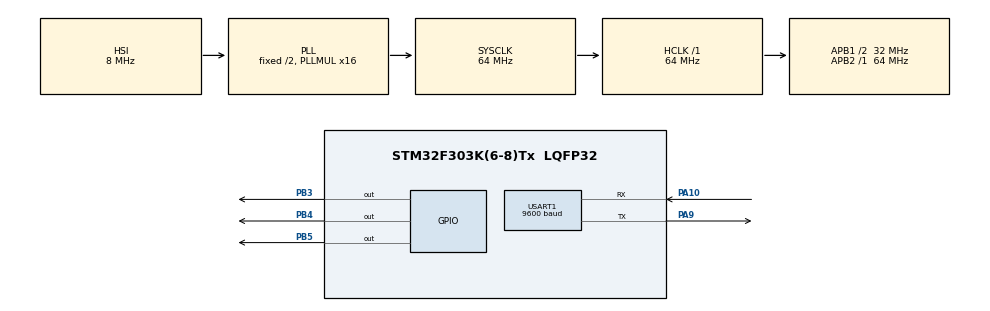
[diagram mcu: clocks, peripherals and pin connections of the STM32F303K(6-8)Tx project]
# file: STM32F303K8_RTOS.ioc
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FREERTOS.INCLUDE_eTaskGetState=1
FREERTOS.INCLUDE_vTaskDelayUntil=1
FREERTOS.Tasks01=defaultTask,3,128,StartDefaultTask,Default,NULL,Dynamic,NULL,NULL;myTask02,2,128,StartTask02,Default,NULL,Dynamic,NULL,NULL;myTask03,1,128,StartTask03,Default,NULL,Dynamic,NULL,NULL
FREERTOS.configCHECK_FOR_STACK_OVERFLOW=1
FREERTOS.configUSE_ALTERNATIVE_API=0
FREERTOS.configUSE_IDLE_HOOK=1
FREERTOS.configUSE_TIMERS=0
Mcu.Family=STM32F3
Mcu.Name=STM32F303K(6-8)Tx
Mcu.Package=LQFP32
NVIC.PriorityGroup=NVIC_PRIORITYGROUP_4
NVIC.TIM1_UP_TIM16_IRQn=true\:0\:0\:false\:false\:true\:false
NVIC.TimeBase=TIM1_UP_TIM16_IRQn
NVIC.TimeBaseIP=TIM1
PA10.Mode=Asynchronous
PA10.Signal=USART1_RX
PA13.GPIO_Label=SWDIO
PA13.Mode=Serial_Wire
PA13.Signal=SYS_JTMS-SWDIO
PA14.GPIO_Label=SWCLK
PA14.Mode=Serial_Wire
PA14.Signal=SYS_JTCK-SWCLK
PA15.GPIO_Label=VCP_RX
PA15.Signal=USART2_RX
PA2.GPIO_Label=VCP_TX
PA2.Signal=USART2_TX
PA9.Mode=Asynchronous
PA9.Signal=USART1_TX
PB3.GPIO_Speed=GPIO_SPEED_FREQ_HIGH
PB3.Signal=GPIO_Output
PB4.GPIO_Speed=GPIO_SPEED_FREQ_HIGH
PB4.Signal=GPIO_Output
PB5.Signal=GPIO_Output
PF0\ /\ OSC_IN.GPIO_Label=MCO
PF0\ /\ OSC_IN.Signal=RCC_OSC_IN
ProjectManager.HeapSize=0x200
ProjectManager.StackSize=0x400
ProjectManager.TargetToolchain=SW4STM32
RCC.ADC1Enable=false
RCC.ADC2Enable=false
RCC.ADC3Enable=false
RCC.ADC4Enable=false
RCC.AHBFreq_Value=64000000
RCC.APB1CLKDivider=RCC_HCLK_DIV2
RCC.APB1Freq_Value=32000000
RCC.APB1TimFreq_Value=64000000
RCC.APB2Freq_Value=64000000
RCC.APB2TimFreq_Value=64000000
RCC.ClockTypeHCLK=RCC_CLOCKTYPE_HCLK
RCC.ClockTypePCLK1=RCC_CLOCKTYPE_PCLK1
RCC.ClockTypePCLK2=RCC_CLOCKTYPE_PCLK2
RCC.CortexFreq_Value=64000000
RCC.EnableHSE=false
RCC.EnableHSERTCDevisor=false
RCC.EnableHSIRTCDevisor=false
RCC.EnableLSE=false
RCC.EnableLSERTC=false
RCC.EnableMCOMultDivisor=false
RCC.FLITFCLKFEnable=false
RCC.HCLKFreq_Value=64000000
RCC.HRTIMEnable=false
RCC.HSEState=RCC_HSE_OFF
RCC.HSE_VALUE=8000000
RCC.HSIState=RCC_HSI_ON
RCC.HSI_VALUE=8000000
RCC.I2C1Enable=false
RCC.I2C2Enable=false
RCC.I2C3Enable=false
RCC.I2SEnable=false
RCC.IWDGEnable=false
RCC.LSIState=RCC_LSI_OFF
RCC.MCOEnable=false
RCC.OscillatorTypeHSI=RCC_OSCILLATORTYPE_HSI
RCC.PLLMUL=RCC_PLL_MUL16
RCC.PLLSource=RCC_PLLSOURCE_HSI
RCC.PLLSourceVirtual=RCC_PLLSOURCE_HSI
RCC.PLLState=RCC_PLL_ON
RCC.RCC_PERIPHCLK_TIM1Var=RCC_PERIPHCLK_TIM1
RCC.RCC_PERIPHCLK_USART1Var=RCC_PERIPHCLK_USART1
RCC.RTCEnable=false
RCC.SYSCLKFreq_VALUE=64000000
RCC.SYSCLKSource=RCC_SYSCLKSOURCE_PLLCLK
RCC.SYSCLKSourceVirtual=RCC_SYSCLKSOURCE_PLLCLK
RCC.Tim15Enable=false
RCC.Tim16Enable=false
RCC.Tim17Enable=false
RCC.Tim1Enable=false
RCC.Tim8Enable=true
RCC.UART4Enable=false
RCC.UART5Enable=false
RCC.USART1Enable=true
RCC.USART2Enable=false
RCC.USART3Enable=false
RCC.USBEnable=false
SYS.instance=TIM1
USART1.BaudRate=9600
USART1.HwFlowCtl-Asynchronous=UART_HWCONTROL_NONE
USART1.VirtualMode-Asynchronous=VM_ASYNC
USART1.WordLength=WORDLENGTH_8B
VP_FREERTOS_VS_ENABLE.Mode=Enabled
VP_SYS_VS_tim1.Mode=TIM1
board=NUCLEO-F303K8

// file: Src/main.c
/**
  ******************************************************************************
  * File Name          : main.c
  * Description        : Main program body
  ******************************************************************************
  *
  * Copyright (c) 2017 STMicroelectronics International N.V.
  * All rights reserved.
  *
  * Redistribution and use in source and binary forms, with or without
  * modification, are permitted, provided that the following conditions are met:
  *
  * 1. Redistribution of source code must retain the above copyright notice,
  *    this list of conditions and the following disclaimer.
  * 2. Redistributions in binary form must reproduce the above copyright notice,
  *    this list of conditions and the following disclaimer in the documentation
  *    and/or other materials provided with the distribution.
  * 3. Neither the name of STMicroelectronics nor the names of other
  *    contributors to this software may be used to endorse or promote products
  *    derived from this software without specific written permission.
  * 4. This software, including modifications and/or derivative works of this
  *    software, must execute solely and exclusively on microcontroller or
  *    microprocessor devices manufactured by or for STMicroelectronics.
  * 5. Redistribution and use of this software other than as permitted under
  *    this license is void and will automatically terminate your rights under
  *    this license.
  *
  * THIS SOFTWARE IS PROVIDED BY STMICROELECTRONICS AND CONTRIBUTORS "AS IS"
  * AND ANY EXPRESS, IMPLIED OR STATUTORY WARRANTIES, INCLUDING, BUT NOT
  * LIMITED TO, THE IMPLIED WARRANTIES OF MERCHANTABILITY, FITNESS FOR A
  * PARTICULAR PURPOSE AND NON-INFRINGEMENT OF THIRD PARTY INTELLECTUAL PROPERTY
  * RIGHTS ARE DISCLAIMED TO THE FULLEST EXTENT PERMITTED BY LAW. IN NO EVENT
  * SHALL STMICROELECTRONICS OR CONTRIBUTORS BE LIABLE FOR ANY DIRECT, INDIRECT,
  * INCIDENTAL, SPECIAL, EXEMPLARY, OR CONSEQUENTIAL DAMAGES (INCLUDING, BUT NOT
  * LIMITED TO, PROCUREMENT OF SUBSTITUTE GOODS OR SERVICES; LOSS OF USE, DATA,
  * OR PROFITS; OR BUSINESS INTERRUPTION) HOWEVER CAUSED AND ON ANY THEORY OF
  * LIABILITY, WHETHER IN CONTRACT, STRICT LIABILITY, OR TORT (INCLUDING
  * NEGLIGENCE OR OTHERWISE) ARISING IN ANY WAY OUT OF THE USE OF THIS SOFTWARE,
  * EVEN IF ADVISED OF THE POSSIBILITY OF SUCH DAMAGE.
  *
  ******************************************************************************
  */
#include "main.h"
#include "stm32f3xx_hal.h"
#include "cmsis_os.h"

UART_HandleTypeDef huart1;

osThreadId defaultTaskHandle;
osThreadId myTask02Handle;
osThreadId myTask03Handle;

/* USER CODE BEGIN PV */
/* Private variables ---------------------------------------------------------*/

/* USER CODE END PV */

void SystemClock_Config(void);
void Error_Handler(void);
static void MX_GPIO_Init(void);
static void MX_USART1_UART_Init(void);
void StartDefaultTask(void const * argument);
void StartTask02(void const * argument);
void StartTask03(void const * argument);

/* USER CODE BEGIN PFP */
/* Private function prototypes -----------------------------------------------*/

/* USER CODE END PFP */

int main(void)
{

  /* MCU Configuration----------------------------------------------------------*/

  /* Reset of all peripherals, Initializes the Flash interface and the Systick. */
  HAL_Init();

  /* Configure the system clock */
  SystemClock_Config();

  /* Initialize all configured peripherals */
  MX_GPIO_Init();
  MX_USART1_UART_Init();

  /* Create the thread(s) */
  /* definition and creation of defaultTask */
  osThreadDef(defaultTask, StartDefaultTask, osPriorityRealtime, 0, 128);
  defaultTaskHandle = osThreadCreate(osThread(defaultTask), NULL);

  /* definition and creation of myTask02 */
  osThreadDef(myTask02, StartTask02, osPriorityHigh, 0, 128);
  myTask02Handle = osThreadCreate(osThread(myTask02), NULL);
//
//  /* definition and creation of myTask03 */
  osThreadDef(myTask03, StartTask03, osPriorityAboveNormal, 0, 128);
  myTask03Handle = osThreadCreate(osThread(myTask03), NULL);

  /* Start scheduler */
  osKernelStart();

  /* We should never get here as control is now taken by the scheduler */

  /* Infinite loop */
  while (1)
  {

  }

}

/** System Clock Configuration
*/
void SystemClock_Config(void)
{

  RCC_OscInitTypeDef RCC_OscInitStruct;
  RCC_ClkInitTypeDef RCC_ClkInitStruct;
  RCC_PeriphCLKInitTypeDef PeriphClkInit;

    /**Initializes the CPU, AHB and APB busses clocks
    */
  RCC_OscInitStruct.OscillatorType = RCC_OSCILLATORTYPE_HSI;
  RCC_OscInitStruct.HSIState = RCC_HSI_ON;
  RCC_OscInitStruct.HSICalibrationValue = 16;
  RCC_OscInitStruct.PLL.PLLState = RCC_PLL_ON;
  RCC_OscInitStruct.PLL.PLLSource = RCC_PLLSOURCE_HSI;
  RCC_OscInitStruct.PLL.PLLMUL = RCC_PLL_MUL16;
  if (HAL_RCC_OscConfig(&RCC_OscInitStruct) != HAL_OK)
  {
    Error_Handler();
  }

    /**Initializes the CPU, AHB and APB busses clocks
    */
  RCC_ClkInitStruct.ClockType = RCC_CLOCKTYPE_HCLK|RCC_CLOCKTYPE_SYSCLK
                              |RCC_CLOCKTYPE_PCLK1|RCC_CLOCKTYPE_PCLK2;
  RCC_ClkInitStruct.SYSCLKSource = RCC_SYSCLKSOURCE_PLLCLK;
  RCC_ClkInitStruct.AHBCLKDivider = RCC_SYSCLK_DIV1;
  RCC_ClkInitStruct.APB1CLKDivider = RCC_HCLK_DIV2;
  RCC_ClkInitStruct.APB2CLKDivider = RCC_HCLK_DIV1;

  if (HAL_RCC_ClockConfig(&RCC_ClkInitStruct, FLASH_LATENCY_2) != HAL_OK)
  {
    Error_Handler();
  }

  PeriphClkInit.PeriphClockSelection = RCC_PERIPHCLK_USART1|RCC_PERIPHCLK_TIM1;
  PeriphClkInit.Usart1ClockSelection = RCC_USART1CLKSOURCE_PCLK1;
  if (HAL_RCCEx_PeriphCLKConfig(&PeriphClkInit) != HAL_OK)
  {
    Error_Handler();
  }

    /**Configure the Systick interrupt time
    */
  HAL_SYSTICK_Config(HAL_RCC_GetHCLKFreq()/1000);

    /**Configure the Systick
    */
  HAL_SYSTICK_CLKSourceConfig(SYSTICK_CLKSOURCE_HCLK);

  /* SysTick_IRQn interrupt configuration */
  HAL_NVIC_SetPriority(SysTick_IRQn, 15, 0);
}

/* USART1 init function */
static void MX_USART1_UART_Init(void)
{

  huart1.Instance = USART1;
  huart1.Init.BaudRate = 9600;
  huart1.Init.WordLength = UART_WORDLENGTH_8B;
  huart1.Init.StopBits = UART_STOPBITS_1;
  huart1.Init.Parity = UART_PARITY_NONE;
  huart1.Init.Mode = UART_MODE_TX_RX;
  huart1.Init.HwFlowCtl = UART_HWCONTROL_NONE;
  huart1.Init.OverSampling = UART_OVERSAMPLING_16;
  huart1.Init.OneBitSampling = UART_ONE_BIT_SAMPLE_DISABLE;
  huart1.AdvancedInit.AdvFeatureInit = UART_ADVFEATURE_NO_INIT;
  if (HAL_UART_Init(&huart1) != HAL_OK)
  {
    Error_Handler();
  }

}

/** Configure pins as
        * Analog
        * Input
        * Output
        * EVENT_OUT
        * EXTI
     PA2   ------> USART2_TX
     PA15   ------> USART2_RX
*/
static void MX_GPIO_Init(void)
{

  GPIO_InitTypeDef GPIO_InitStruct;

  /* GPIO Ports Clock Enable */
  __HAL_RCC_GPIOF_CLK_ENABLE();
  __HAL_RCC_GPIOA_CLK_ENABLE();
  __HAL_RCC_GPIOB_CLK_ENABLE();

  /*Configure GPIO pin Output Level */
  HAL_GPIO_WritePin(GPIOB, GPIO_PIN_3|GPIO_PIN_4|GPIO_PIN_5, GPIO_PIN_RESET);

  /*Configure GPIO pins : VCP_TX_Pin VCP_RX_Pin */
  GPIO_InitStruct.Pin = VCP_TX_Pin|VCP_RX_Pin;
  GPIO_InitStruct.Mode = GPIO_MODE_AF_PP;
  GPIO_InitStruct.Pull = GPIO_NOPULL;
  GPIO_InitStruct.Speed = GPIO_SPEED_FREQ_HIGH;
  GPIO_InitStruct.Alternate = GPIO_AF7_USART2;
  HAL_GPIO_Init(GPIOA, &GPIO_InitStruct);

  /*Configure GPIO pins : PB3 PB4 */
  GPIO_InitStruct.Pin = GPIO_PIN_3|GPIO_PIN_4;
  GPIO_InitStruct.Mode = GPIO_MODE_OUTPUT_PP;
  GPIO_InitStruct.Pull = GPIO_NOPULL;
  GPIO_InitStruct.Speed = GPIO_SPEED_FREQ_HIGH;
  HAL_GPIO_Init(GPIOB, &GPIO_InitStruct);

  /*Configure GPIO pin : PB5 */
  GPIO_InitStruct.Pin = GPIO_PIN_5;
  GPIO_InitStruct.Mode = GPIO_MODE_OUTPUT_PP;
  GPIO_InitStruct.Pull = GPIO_NOPULL;
  GPIO_InitStruct.Speed = GPIO_SPEED_FREQ_LOW;
  HAL_GPIO_Init(GPIOB, &GPIO_InitStruct);

}

/* StartDefaultTask function */
void StartDefaultTask(void const * argument)
{

  /* USER CODE BEGIN 5 */
  /* Infinite loop */
  uint32_t PreviousWakeTime = osKernelSysTick();
  for(;;)
  {
	  HAL_GPIO_TogglePin(GPIOB, GPIO_PIN_3);
	  //osDelay(1);
	  osDelayUntil (&PreviousWakeTime, 1);
  }
  /* USER CODE END 5 */
}

/* StartTask02 function */
void StartTask02(void const * argument)
{
  /* USER CODE BEGIN StartTask02 */
  /* Infinite loop */
  uint32_t PreviousWakeTime = osKernelSysTick();
  for(;;)
  {
	HAL_GPIO_TogglePin(GPIOB, GPIO_PIN_4);
    //osDelay(1);
    osDelayUntil (&PreviousWakeTime, 1);
  }
  /* USER CODE END StartTask02 */
}

/* StartTask03 function */
void StartTask03(void const * argument)
{
  /* USER CODE BEGIN StartTask03 */
  /* Infinite loop */
  uint32_t PreviousWakeTime = osKernelSysTick();
  for(;;)
  {
	  HAL_GPIO_TogglePin(GPIOB, GPIO_PIN_5);
    //osDelay(1);
	  osDelayUntil (&PreviousWakeTime, 1);
  }
  /* USER CODE END StartTask03 */
}

void HAL_TIM_PeriodElapsedCallback(TIM_HandleTypeDef *htim)
{
  if (htim->Instance == TIM1) {
    HAL_IncTick();
  }
}

void Error_Handler(void)
{
  while(1)
  {
  }
}

/************************ (C) COPYRIGHT STMicroelectronics *****END OF FILE****/

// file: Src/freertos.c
/**
  ******************************************************************************
  * File Name          : freertos.c
  * Description        : Code for freertos applications
  ******************************************************************************
  *
  * Copyright (c) 2017 STMicroelectronics International N.V.
  * All rights reserved.
  *
  * Redistribution and use in source and binary forms, with or without
  * modification, are permitted, provided that the following conditions are met:
  *
  * 1. Redistribution of source code must retain the above copyright notice,
  *    this list of conditions and the following disclaimer.
  * 2. Redistributions in binary form must reproduce the above copyright notice,
  *    this list of conditions and the following disclaimer in the documentation
  *    and/or other materials provided with the distribution.
  * 3. Neither the name of STMicroelectronics nor the names of other
  *    contributors to this software may be used to endorse or promote products
  *    derived from this software without specific written permission.
  * 4. This software, including modifications and/or derivative works of this
  *    software, must execute solely and exclusively on microcontroller or
  *    microprocessor devices manufactured by or for STMicroelectronics.
  * 5. Redistribution and use of this software other than as permitted under
  *    this license is void and will automatically terminate your rights under
  *    this license.
  *
  * THIS SOFTWARE IS PROVIDED BY STMICROELECTRONICS AND CONTRIBUTORS "AS IS"
  * AND ANY EXPRESS, IMPLIED OR STATUTORY WARRANTIES, INCLUDING, BUT NOT
  * LIMITED TO, THE IMPLIED WARRANTIES OF MERCHANTABILITY, FITNESS FOR A
  * PARTICULAR PURPOSE AND NON-INFRINGEMENT OF THIRD PARTY INTELLECTUAL PROPERTY
  * RIGHTS ARE DISCLAIMED TO THE FULLEST EXTENT PERMITTED BY LAW. IN NO EVENT
  * SHALL STMICROELECTRONICS OR CONTRIBUTORS BE LIABLE FOR ANY DIRECT, INDIRECT,
  * INCIDENTAL, SPECIAL, EXEMPLARY, OR CONSEQUENTIAL DAMAGES (INCLUDING, BUT NOT
  * LIMITED TO, PROCUREMENT OF SUBSTITUTE GOODS OR SERVICES; LOSS OF USE, DATA,
  * OR PROFITS; OR BUSINESS INTERRUPTION) HOWEVER CAUSED AND ON ANY THEORY OF
  * LIABILITY, WHETHER IN CONTRACT, STRICT LIABILITY, OR TORT (INCLUDING
  * NEGLIGENCE OR OTHERWISE) ARISING IN ANY WAY OUT OF THE USE OF THIS SOFTWARE,
  * EVEN IF ADVISED OF THE POSSIBILITY OF SUCH DAMAGE.
  *
  ******************************************************************************
  */

#include "FreeRTOS.h"
#include "task.h"

/* Hook prototypes */
void vApplicationIdleHook(void);
void vApplicationStackOverflowHook(xTaskHandle xTask, signed char *pcTaskName);

/* USER CODE BEGIN 2 */
__weak void vApplicationIdleHook( void )
{
   /* vApplicationIdleHook() will only be called if configUSE_IDLE_HOOK is set
   to 1 in FreeRTOSConfig.h. It will be called on each iteration of the idle
   task. It is essential that code added to this hook function never attempts
   to block in any way (for example, call xQueueReceive() with a block time
   specified, or call vTaskDelay()). If the application makes use of the
   vTaskDelete() API function (as this demo application does) then it is also
   important that vApplicationIdleHook() is permitted to return to its calling
   function, because it is the responsibility of the idle task to clean up
   memory allocated by the kernel to any task that has since been deleted. */
}
/* USER CODE END 2 */

/* USER CODE BEGIN 4 */
__weak void vApplicationStackOverflowHook(xTaskHandle xTask, signed char *pcTaskName)
{
   /* Run time stack overflow checking is performed if
   configCHECK_FOR_STACK_OVERFLOW is defined to 1 or 2. This hook function is
   called if a stack overflow is detected. */
}
/* USER CODE END 4 */

/************************ (C) COPYRIGHT STMicroelectronics *****END OF FILE****/
